# Port_A_3 register map
Vendor: Texas Instruments
Peripheral module from a debugger description file (folder msp430).
Registers are 16-bit, read-write, reset 0x0 unless marked. A register's access mark holds for its fields unless they carry their own. Offsets are as the file gives them; lines under a group give offsets from that group; [hi:lo] are bit positions; {n}, {i} and the like mark numbered series; 'fields as' and 'values as' point back to an identical list; <NAME> marks a mode.

## Port_A
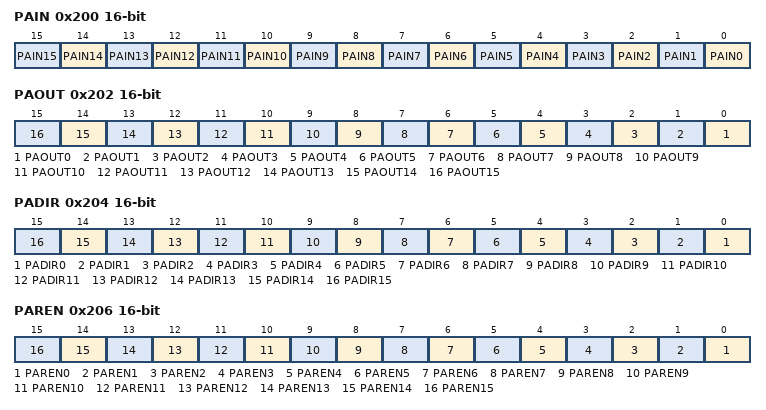
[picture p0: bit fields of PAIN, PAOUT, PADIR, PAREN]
0x200 PAIN — Port A Input
  [n] PAIN{n} (n=0..15)
0x202 PAOUT — Port A Output
  [n] PAOUT{n} (n=0..15)
0x204 PADIR — Port A Direction
  [n] PADIR{n} (n=0..15)
0x206 PAREN — Port A Resistor Enable
  [n] PAREN{n} (n=0..15)
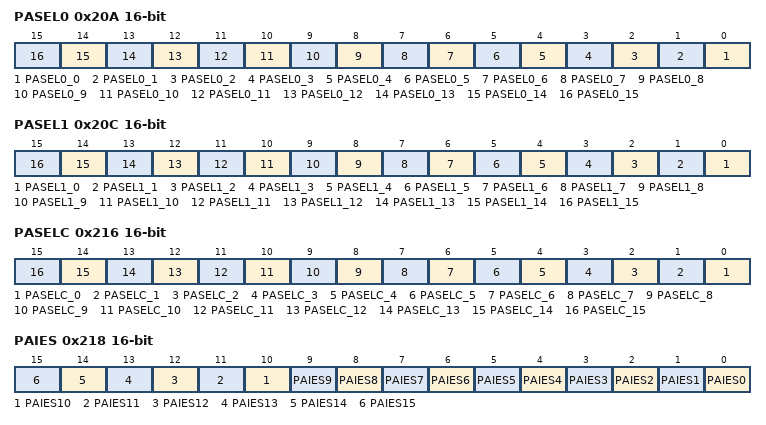
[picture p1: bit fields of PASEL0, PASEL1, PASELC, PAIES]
0x20A PASEL0 — Port A Selection 0
  [n] PASEL0_{n} (n=0..15)
0x20C PASEL1 — Port A Selection 1
  [n] PASEL1_{n} (n=0..15)
0x216 PASELC — Port A Complement Selection
  [n] PASELC_{n} (n=0..15)
0x218 PAIES — Port A Interrupt Edge Select
  [n] PAIES{n} (n=0..15)
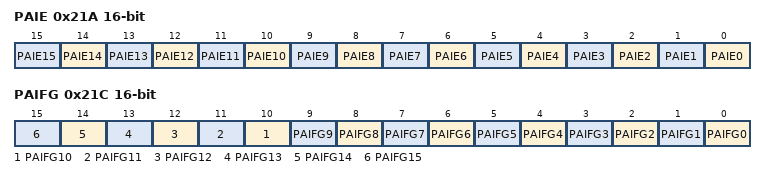
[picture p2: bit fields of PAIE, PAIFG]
0x21A PAIE — Port A Interrupt Enable
  [n] PAIE{n} (n=0..15)
0x21C PAIFG — Port A Interrupt Flag
  [n] PAIFG{n} (n=0..15)
